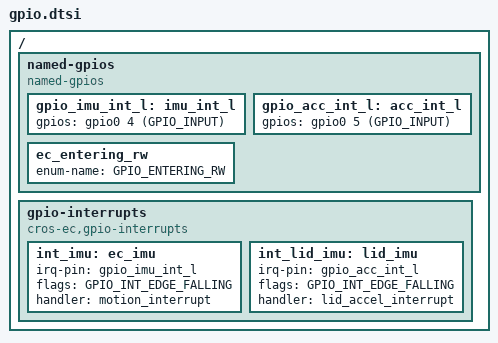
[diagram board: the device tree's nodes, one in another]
/* Copyright 2025 The ChromiumOS Authors
 * Use of this source code is governed by a BSD-style license that can be
 * found in the LICENSE file.
 */

#include "dt-bindings/gpio_defines.h"

/ {
	named-gpios {
		compatible = "named-gpios";

		gpio_imu_int_l: imu_int_l {
			gpios = <&gpio0 4 (GPIO_INPUT)>;
		};
		gpio_acc_int_l: acc_int_l {
			gpios = <&gpio0 5 (GPIO_INPUT)>;
		};
		ec_entering_rw {
			enum-name = "GPIO_ENTERING_RW";
		};
	};
	gpio-interrupts {
		compatible = "cros-ec,gpio-interrupts";

		int_imu: ec_imu {
			irq-pin = <&gpio_imu_int_l>;
			flags = <GPIO_INT_EDGE_FALLING>;
			handler = "motion_interrupt";
		};
		int_lid_imu: lid_imu {
			irq-pin = <&gpio_acc_int_l>;
			flags = <GPIO_INT_EDGE_FALLING>;
			handler = "lid_accel_interrupt";
		};
	};
};
